AUTOSAR XML (schema 4-2-2)
package /BMW/Platform/StdDiag/SwcImplementations
  swc implementation Impl_StdDiag: behavior=IntBhv_StdDiag
    code-descriptors:
      code Default: artifact-descriptors=autosar-engineering-object={short-label=Default, category=SWSRC}
package /BMW/Platform/StdDiag/SwComponentTypes
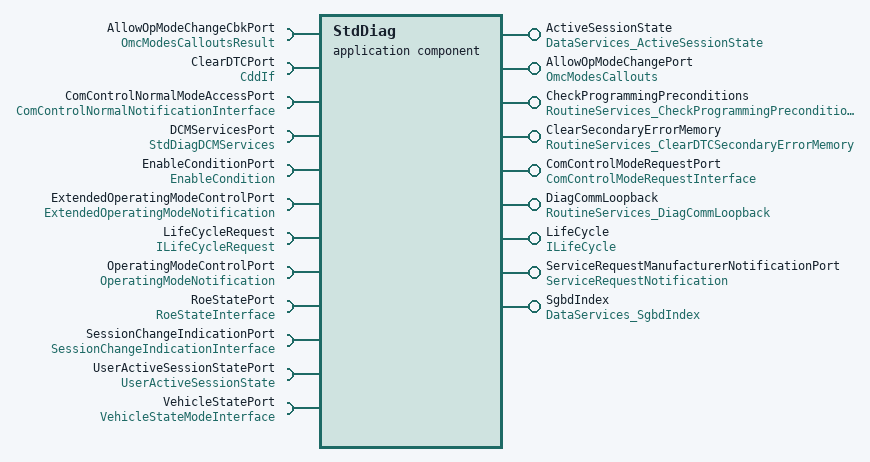
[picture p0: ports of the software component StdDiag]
  application sw component type StdDiag
    9 x provide port:
      ActiveSessionState: provided-com-specs=[{operation=ConditionCheckRead, queue-length=1}, {operation=ReadData, queue-length=1}], provided-interface=DataServices_ActiveSessionState
      AllowOpModeChangePort: provided-com-specs=[{operation=AllowOpModeSwitch, queue-length=1}, {operation=OpModeSwitchCancelled, queue-length=1}], provided-interface=OmcModesCallouts
      CheckProgrammingPreconditions: server-com-spec{operation=Start, queue-length=1}, provided-interface=RoutineServices_CheckProgrammingPreconditions
      ClearSecondaryErrorMemory: server-com-spec{operation=Start, queue-length=1}, provided-interface=RoutineServices_ClearDTCSecondaryErrorMemory
      ComControlModeRequestPort: nonqueued-sender-com-spec=data-element=requestedMode, provided-interface=ComControlModeRequestInterface
      DiagCommLoopback: server-com-spec{operation=Start, queue-length=1}, provided-interface=RoutineServices_DiagCommLoopback
      LifeCycle: mode-switch-sender-com-spec{enhanced-mode-api=true, mode-group=Mode, queue-length=2}, provided-interface=ILifeCycle
      ServiceRequestManufacturerNotificationPort: provided-com-specs=[{operation=Confirmation, queue-length=1}, {operation=Indication, queue-length=1}], provided-interface=ServiceRequestNotification
      SgbdIndex: server-com-spec{operation=ReadData, queue-length=1}, provided-interface=DataServices_SgbdIndex
    12 x require port:
      AllowOpModeChangeCbkPort: required-com-specs=[OpModeSwitchAllowedResult, OpModeSwitchCancelledAck], required-interface=OmcModesCalloutsResult
      ClearDTCPort: client-com-spec=ClearDTC, required-interface=CddIf
      ComControlNormalModeAccessPort: mode-switch-receiver-com-spec{enhanced-mode-api=false, supports-asynchronous-mode-switch=false}, required-interface=ComControlNormalNotificationInterface
      DCMServicesPort: client-com-spec=GetSesCtrlType, required-interface=StdDiagDCMServices
      EnableConditionPort: client-com-spec=SetEnableCondition, required-interface=EnableCondition
      ExtendedOperatingModeControlPort: mode-switch-receiver-com-spec{enhanced-mode-api=false, supports-asynchronous-mode-switch=false}, required-interface=ExtendedOperatingModeNotification
      LifeCycleRequest: nonqueued-receiver-com-spec{data-element=requestMode, filter=data-filter-type=ALWAYS, init-value=2}, required-interface=ILifeCycleRequest
      OperatingModeControlPort: mode-switch-receiver-com-spec{enhanced-mode-api=false, supports-asynchronous-mode-switch=false}, required-interface=OperatingModeNotification
      RoeStatePort: client-com-spec=GetRoeState, required-interface=RoeStateInterface
      SessionChangeIndicationPort: mode-switch-receiver-com-spec{enhanced-mode-api=false, supports-asynchronous-mode-switch=false}, required-interface=SessionChangeIndicationInterface
      UserActiveSessionStatePort: client-com-spec=GetActiveSessionState, required-interface=UserActiveSessionState
      VehicleStatePort: mode-switch-receiver-com-spec{enhanced-mode-api=false, supports-asynchronous-mode-switch=false}, required-interface=VehicleStateModeInterface
    behavior IntBhv_StdDiag: data-type-mapping=[Stm_VehicleStatModeRequestTypeMap, StdDiag_DataTypeMappingSet, Omc_DataTypeMappingSets]
      operation invoked event Event_AllowOpModeChange: start-on-event=AllowOpModeChange, operation=AllowOpModeChangePort.AllowOpModeSwitch
      operation invoked event Event_ConditionCheckActiveSessionState: start-on-event=ConditionCheckActiveSessionState, operation=ActiveSessionState.ConditionCheckRead
      data received event LifeCycleRequest: start-on-event=LifeCycleHandler, data=LifeCycleRequest.requestMode
      8 x operation invoked event:
        Event_ManufacturerConfirmation: start-on-event=ManufacturerConfirmation, operation=ServiceRequestManufacturerNotificationPort.Confirmation
        Event_ManufacturerIndication: start-on-event=ManufacturerIndication, operation=ServiceRequestManufacturerNotificationPort.Indication
        Event_OpModeChangeCancelled: start-on-event=OpModeChangeCancelled, operation=AllowOpModeChangePort.OpModeSwitchCancelled
        Event_ReadDataActiveSessionState: start-on-event=ReadDataActiveSessionState, operation=ActiveSessionState.ReadData
        Event_ReadDataSgbdIndex: start-on-event=ReadDataSgbdIndex, operation=SgbdIndex.ReadData
        Event_RoutineControlStartCheckProgrammingPreconditions: start-on-event=RoutineControlStartCheckProgrammingPreconditions, operation=CheckProgrammingPreconditions.Start
        Event_RoutineControlStartClearDTCSecondaryErrorMemory: start-on-event=RoutineControlStartClearDTCSecondaryErrorMemory, operation=ClearSecondaryErrorMemory.Start
        Event_RoutineControlStartDiagCommLoopback: start-on-event=RoutineControlStartDiagCommLoopback, operation=DiagCommLoopback.Start
      swc mode switch event Event_SessionChange_DefaultSession: start-on-event=SessionChange_DefaultSession, activation=ON-ENTRY, mode=SessionChangeIndicationPort.SessionModeDeclarationGroup.STDDIAG_DEFAULT_SESSION
      swc mode switch event Event_SessionChange_OtherSession: start-on-event=SessionChange_OtherSession, activation=ON-ENTRY, mode=SessionChangeIndicationPort.SessionModeDeclarationGroup.STDDIAG_OTHER_SESSION
      13 x runnable:
        AllowOpModeChange: can-be-invoked-concurrently=true, mode-access-point=VehicleStatePort.currentVehicleStateMode, symbol=StdDiag_AllowOpModeChange
        ConditionCheckActiveSessionState: can-be-invoked-concurrently=true, symbol=StdDiag_ConditionCheckActiveSessionState
          sync call sscp_activeSessionStateHddUpdate: operation=UserActiveSessionStatePort.GetActiveSessionState, timeout=0
          sync call sscp_DcmGetSesCtrlType: operation=DCMServicesPort.GetSesCtrlType, timeout=0
        LifeCycleHandler: symbol=StdDiag_LifeCycleHandler
          data-read-access:
            access requestedMode: accessed-variable=LifeCycleRequest.requestMode
          data-send-points:
            access VariableAccess_requestComMode: accessed-variable=ComControlModeRequestPort.requestedMode
          mode-access-points:
            LifeCycle.Mode
            ExtendedOperatingModeControlPort.currentExtendedOperatingMode
            OperatingModeControlPort.currentOperatingMode
          mode switch point LifeCycle: mode-group=LifeCycle.Mode
          sync call sscp_DcmGetSesCtrlType: operation=DCMServicesPort.GetSesCtrlType, timeout=0
          sync call sscp_EnableCondition: operation=EnableConditionPort.SetEnableCondition, timeout=0
          sync call sscp_SetRoeSuspended: operation=RoeStatePort.GetRoeState, timeout=0
        ManufacturerConfirmation: can-be-invoked-concurrently=true, symbol=StdDiag_ManufacturerConfirmation
          data-send-points:
            access VariableAccess_requestComMode: accessed-variable=ComControlModeRequestPort.requestedMode
          mode-access-points:
            OperatingModeControlPort.currentOperatingMode
            ComControlNormalModeAccessPort.CommunicationModeDeclarationGroup
            ExtendedOperatingModeControlPort.currentExtendedOperatingMode
          sync call sscp_EnableCondition: operation=EnableConditionPort.SetEnableCondition, timeout=0
          sync call sscp_SetRoeSuspended: operation=RoeStatePort.GetRoeState, timeout=0
        ManufacturerIndication: can-be-invoked-concurrently=true, mode-access-point=OperatingModeControlPort.currentOperatingMode, symbol=StdDiag_ManufacturerIndication
        OpModeChangeCancelled: can-be-invoked-concurrently=true, symbol=StdDiag_OpModeChangeCancelled
        ReadDataActiveSessionState: can-be-invoked-concurrently=true, symbol=StdDiag_ReadActiveSessionState
        ReadDataSgbdIndex: can-be-invoked-concurrently=true, symbol=StdDiag_ReadSgbdIndex
        RoutineControlStartCheckProgrammingPreconditions: can-be-invoked-concurrently=true, symbol=StdDiag_RoutineControlStartCheckProgrammingPreconditions
        RoutineControlStartClearDTCSecondaryErrorMemory: can-be-invoked-concurrently=true, symbol=StdDiag_RoutineControlStartClearDTCSecondaryErrorMemory
          sync call sscp_ClearDTC: operation=ClearDTCPort.ClearDTC, timeout=0
        RoutineControlStartDiagCommLoopback: can-be-invoked-concurrently=true, symbol=StdDiag_RoutineControlStartDiagCommLoopback
        SessionChange_DefaultSession: symbol=StdDiag_SesChgIndication_DefaultSession
          data-send-points:
            access VariableAccess_requestComMode: accessed-variable=ComControlModeRequestPort.requestedMode
          mode-access-points:
            OperatingModeControlPort.currentOperatingMode
            ComControlNormalModeAccessPort.CommunicationModeDeclarationGroup
            ExtendedOperatingModeControlPort.currentExtendedOperatingMode
          sync call sscp_EnableCondition: operation=EnableConditionPort.SetEnableCondition, timeout=0
          sync call sscp_SetRoeSuspended: operation=RoeStatePort.GetRoeState, timeout=0
        SessionChange_OtherSession: symbol=StdDiag_SesChgIndication_OtherSession
      7 x swc service dependency:
        StdDiag_DiagnosticCommunicationManagerServiceNeeds_DCMServices: assigned-ports=role-based-port-assignment={port-prototype=DCMServicesPort, role=DCMServices}
          service-needs:
            diagnostic communication manager needs sn_StdDiag_DiagnosticCommunicationManagerServiceNeeds_DCMServices
        StdDiag_DiagnosticCommunicationManagerServiceNeeds_ServiceRequestNotification: assigned-ports=role-based-port-assignment={port-prototype=ServiceRequestManufacturerNotificationPort, role=ServiceRequestNotification}
          service-needs:
            diagnostic communication manager needs sn_StdDiag_DiagnosticCommunicationManagerServiceNeeds
        StdDiag_DiagnosticEventManagerServiceNeeds_EnableCondition: assigned-ports=role-based-port-assignment={port-prototype=EnableConditionPort, role=EnableCondition}
          service-needs:
            diagnostic event manager needs sn_StdDiag_DiagnosticEventManagerServiceNeeds_EnableCondition
        StdDiag_DiagnosticValueServiceNeeds_ActiveSessionState: assigned-ports=role-based-port-assignment={port-prototype=ActiveSessionState, role=DataServices}
          service-needs:
            diagnostic value needs sn_StdDiag_DiagnosticValueServiceNeeds_ActiveSessionState: did-number=61696
        StdDiag_DiagnosticRoutineServiceNeeds_CheckProgrammingPreconditions: assigned-ports=role-based-port-assignment={port-prototype=CheckProgrammingPreconditions, role=RoutineServices}
          service-needs:
            diagnostic routine needs sn_StdDiag_DiagnosticRoutingServiceNeeds_CheckProgrammingPreconditions: diag-routine-type=SYNCHRONOUS, rid-number=515
        StdDiag_DiagnosticRoutineServiceNeeds_ClearDTCSecondaryErrorMemory: assigned-ports=role-based-port-assignment={port-prototype=ClearSecondaryErrorMemory, role=RoutineServices}
          service-needs:
            diagnostic routine needs sn_StdDiag_DiagnosticRoutineServiceNeeds_ClearDTCSecondaryErrorMemory: diag-routine-type=ASYNCHRONOUS, rid-number=3846
        StdDiag_DiagnosticRoutineServiceNeeds_DiagCommLoopBack: assigned-ports=role-based-port-assignment={port-prototype=DiagCommLoopback, role=RoutineServices}
          service-needs:
            diagnostic routine needs sn_StdDiag_DiagnosticRoutingServiceNeeds_DiagCommLoopBack: diag-routine-type=SYNCHRONOUS, rid-number=771
